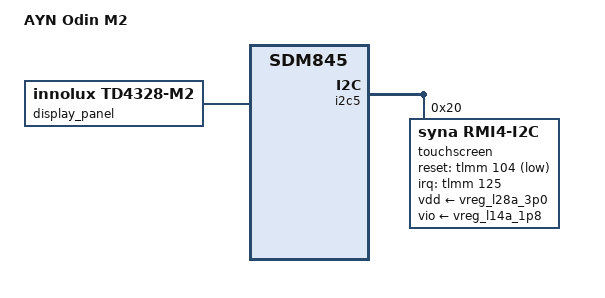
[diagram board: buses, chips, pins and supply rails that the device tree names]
// SPDX-License-Identifier: GPL-2.0
/*
 * Copyright (c) 2024, Anton Bambura.
 *
 * AYN Odin with the second panel revision (Odin M2 / "v2 screen").
 */

/dts-v1/;

#include "sdm845-ayn-odin.dts"

/ {
	model = "AYN Odin M2";
	compatible = "ayn,odin-m2", "ayn,odin", "qcom,sdm845";
};

&display_panel {
	compatible = "innolux,td4328-m2";
	rotation = <270>;
};

&{/rocknix,device_switch} {
	this = "odin-m2";
};

&ts_reset_active {
	output-high;
};

&i2c5 {
	/delete-node/ touchscreen@70;

	touchscreen@20 {
		compatible = "syna,rmi4-i2c";
		reg = <0x20>;
		#address-cells = <1>;
		#size-cells = <0>;
		reset-gpios = <&tlmm 104 GPIO_ACTIVE_LOW>;
		interrupts-extended = <&tlmm 125 IRQ_TYPE_EDGE_FALLING>;
		vdd-supply = <&vreg_l28a_3p0>;
		vio-supply = <&vreg_l14a_1p8>;
		syna,reset-delay-ms = <200>;
		syna,startup-delay-ms = <200>;
		panel = <&display_panel>;
		pinctrl-names = "default";
		pinctrl-0 = <&ts_int_active &ts_reset_active>;

		rmi4-f01@1 {
			reg = <0x01>;
			syna,nosleep-mode = <1>;
		};

		rmi4-f12@12 {
			reg = <0x12>;
			touchscreen-inverted-x;
			touchscreen-x-mm = <75>;
			touchscreen-y-mm = <132>;
			syna,sensor-type = <1>;
			syna,rezero-wait-ms = <200>;
		};
	};
};
